# STM32MP13xx register map
File version: 1.5
CPU: CA7 r0p0, little endian, MPU, FPU, 4 interrupt priority bits
Registers are 32-bit, read-write, reset 0x0 unless marked. A register's access mark holds for its fields unless they carry their own. Offsets are from the block's base; [hi:lo] are bit positions; {n}, {i} and the like mark numbered series.

## SPDIFRX
Base 0x4000D000
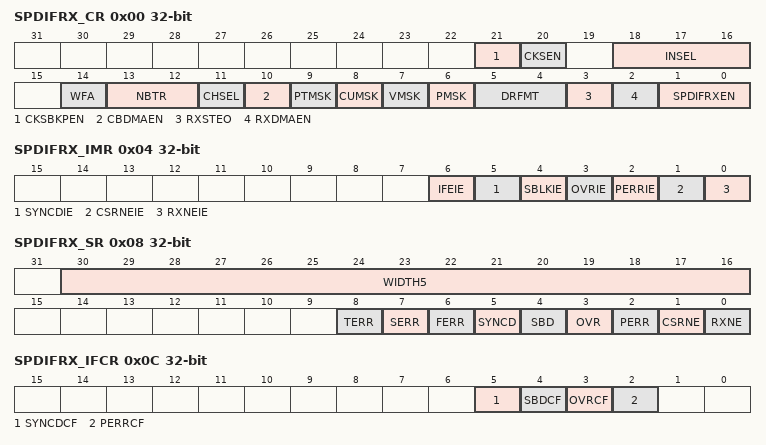
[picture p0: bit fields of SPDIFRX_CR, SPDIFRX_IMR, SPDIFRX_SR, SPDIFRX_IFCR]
0x00 SPDIFRX_CR — Control register
  [21] CKSBKPEN, [20] CKSEN, [18:16] INSEL, [14] WFA, [13:12] NBTR, [11] CHSEL, [10] CBDMAEN, [9] PTMSK, [8] CUMSK, [7] VMSK, [6] PMSK, [5:4] DRFMT, [3] RXSTEO, [2] RXDMAEN, [1:0] SPDIFRXEN
0x04 SPDIFRX_IMR — Interrupt mask register
  [6] IFEIE, [5] SYNCDIE, [4] SBLKIE, [3] OVRIE, [2] PERRIE, [1] CSRNEIE, [0] RXNEIE
0x08 SPDIFRX_SR ro — Status register
  [30:16] WIDTH5, [8] TERR, [7] SERR, [6] FERR, [5] SYNCD, [4] SBD, [3] OVR, [2] PERR, [1] CSRNE, [0] RXNE
0x0C SPDIFRX_IFCR — Interrupt flag clear register
  [5] SYNCDCF wo, [4] SBDCF wo, [3] OVRCF wo, [2] PERRCF wo
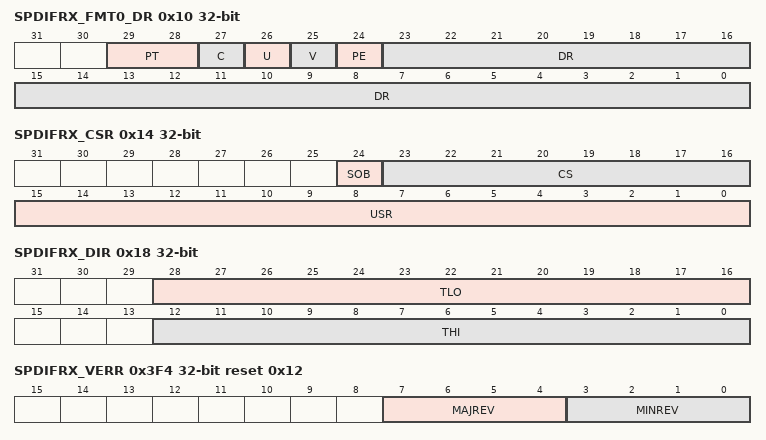
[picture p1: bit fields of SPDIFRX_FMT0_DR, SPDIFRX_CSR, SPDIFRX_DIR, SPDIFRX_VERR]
0x10 SPDIFRX_FMT0_DR ro — This register can take 3 different formats according to DRFMT. Here is the format when DRFMT = 00:
  [29:28] PT, [27] C, [26] U, [25] V, [24] PE, [23:0] DR
0x14 SPDIFRX_CSR ro — Channel status register
  [24] SOB, [23:16] CS, [15:0] USR
0x18 SPDIFRX_DIR ro — Debug information register
  [28:16] TLO, [12:0] THI
0x3F4 SPDIFRX_VERR ro reset 0x12 — SPDIFRX version register
  [7:4] MAJREV, [3:0] MINREV
0x3F8 SPDIFRX_IPIDR ro reset 0x130041 — SPDIFRX identification register
  [31:0] ID
0x3FC SPDIFRX_SIDR ro reset 0xA3C5DD01 — SPDIFRX size identification register
  [31:0] SID

## STGENR
Base 0x5A005000
0x00 STGENR_CNTCVL ro — STGENR value lower register
  [31:0] CNTCVL_L_32 — current value of the timestamp counter (the lower 32 bits)
0x04 STGENR_CNTCVU ro — STGENR value upper register
  [31:0] CNTCVU_U_32 — current value of the timestamp counter (the upper 32 bits)
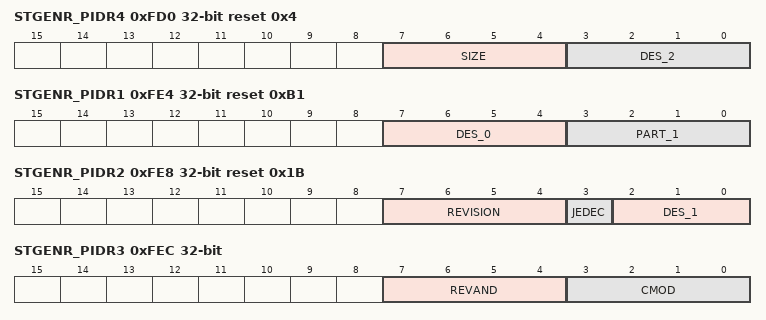
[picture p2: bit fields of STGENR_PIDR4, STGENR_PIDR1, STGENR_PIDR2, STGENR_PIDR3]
0xFD0 STGENR_PIDR4 ro reset 0x4 — STGENR peripheral ID4 register
  [7:4] SIZE — always 0b0000 Indicates that the device only occupies 4 Kbytes of memory.
  [3:0] DES_2 — part of designer identification Together PIDR1.DES_0, PIDR2.DES_1, and PIDR4.DES_2 identify the designer of the component.
{0xFC0+4i} STGENR_PIDR{i} ro (i=5..7) — STGENR peripheral ID{i} register
  [31:0] PIDR{i} — peripheral ID{i}
0xFE0 STGENR_PIDR0 ro reset 0x1 — STGENR peripheral ID0 register
  [7:0] PART_0 — bits[7:0] of the 12-bit part number of the component.
0xFE4 STGENR_PIDR1 ro reset 0xB1 — STGENR peripheral ID1 register
  [7:4] DES_0 — part of designer identification Together PIDR1.DES_0, PIDR2.DES_1, and PIDR4.DES_2 identify the designer of the component.
  [3:0] PART_1 — Bits[11:8] of the 12-bit part number of the component
0xFE8 STGENR_PIDR2 ro reset 0x1B — STGENR peripheral ID2 register
  [7:4] REVISION — device revision number
  [3] JEDEC — always 1 Indicates that the JEDEC-assigned designer ID is used.
  [2:0] DES_1 — part of designer identification Together PIDR1.DES_0, PIDR2.DES_1, and PIDR4.DES_2, identify the designer of the component.
0xFEC STGENR_PIDR3 ro — STGENR peripheral ID3 register
  [7:4] REVAND — errata fix identification 0b0000 indicates there are no errata fixes to this component.
  [3:0] CMOD — customer modified Indicates whether the customer has modified the behavior of the component. In most cases, this field is 0b0000 (no modification done). Customers change this value when they make authorized modifications to this component.
0xFF0 STGENR_CIDR0 ro reset 0xD — STGENR component ID0 register
  [7:0] PRMBL_0 — preamble 0 Contains bits[7:0] of the component identification code.
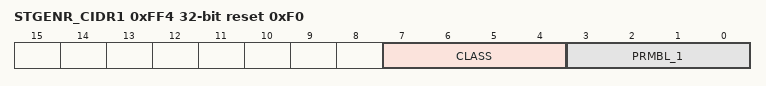
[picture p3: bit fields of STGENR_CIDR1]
0xFF4 STGENR_CIDR1 ro reset 0xF0 — STGENR component ID1 register
  [7:4] CLASS — class of the component Contains bits[15:12] of the component identification code.
  [3:0] PRMBL_1 — preamble 1 Contains bits[11:8] of the component identification code.
0xFF8 STGENR_CIDR2 ro reset 0x50 — STGENR component ID2 register
  [7:0] PRMBL_2 — preamble 2 Contains bits[23:16] of the component identification code.
0xFFC STGENR_CIDR3 ro reset 0xB1 — STGENR component ID3 register
  [7:0] PRMBL_3 — preamble 3 Contains bits[31:24] of the component identification code.
